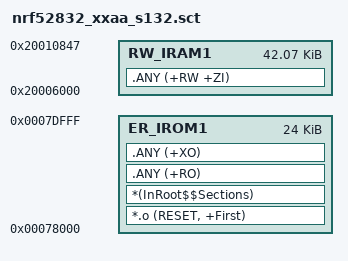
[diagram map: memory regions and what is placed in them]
; *************************************************************
; *** Scatter-Loading Description File generated by uVision ***
; *************************************************************

LR_IROM1 0x00078000 0x00006000  {    ; load region size_region
  ER_IROM1 0x00078000 0x00006000  {  ; load address = execution address
   *.o (RESET, +First)
   *(InRoot$$Sections)
   .ANY (+RO)
   .ANY (+XO)
  }
  RW_IRAM1 0x20006000 0x0000A848  {  ; RW data
   .ANY (+RW +ZI)
  }
}

